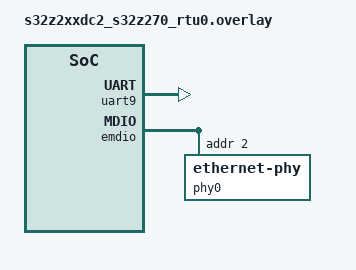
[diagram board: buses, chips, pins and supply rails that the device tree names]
/*
 * Copyright (c) 2022-2023, Arm Limited.
 * SPDX-License-Identifier: Apache-2.0
 */

/{
	soc {
		sram2: memory@32100000 {
			compatible = "mmio-sram";
			reg = <0x32100000 DT_SIZE_M(7)>;
		};
	};

	chosen {
		zephyr,sram = &sram2;
	};
};

&enetc_psi0 {
	local-mac-address = [BA DA 01 04 57 E2];
};
/* ARM Automotive Kit board revision D (was boards/s32z270dc2_rtu0_r52@D.overlay). */

/*
 * ARM Automotive Kit UART configuration
 * Uses UART9 instead of UART0 for console output
 * Required for ARM board vs standard NXP evaluation board
 */

/ {
	chosen {
		zephyr,console = &uart9;
		zephyr,shell-uart = &uart9;
		zephyr,canbus = &can0;
	};
};

&uart9 {
	pinctrl-0 = <&uart9_default>;
	pinctrl-names = "default";
	status = "okay";
};

&emdio {
    /delete-node/ ethernet-phy@7;

    phy0: ethernet-phy@2 {
        compatible = "ethernet-phy";
        reg = <0x2>;
        status = "okay";
    };
};
